# AVR64EA48 device description
Architecture: AVR8X; Family: AVR
Registers are 8-bit, read-write, reset 0x0 unless marked. A register's access mark holds for its fields unless they carry their own. Offsets are from the block's base; [hi:lo] are bit positions; {n}, {i} and the like mark numbered series; 'fields as' and 'values as' point back to an identical list.

## PORT — I/O Ports
Instances: PORTA 0x0400, PORTB 0x0420, PORTC 0x0440, PORTD 0x0460, PORTE 0x0480, PORTF 0x04A0
0x00 DIR — Data Direction
0x01 DIRSET — Data Direction Set
0x02 DIRCLR — Data Direction Clear
0x03 DIRTGL — Data Direction Toggle
0x04 OUT — Output Value
0x05 OUTSET — Output Value Set
0x06 OUTCLR — Output Value Clear
0x07 OUTTGL — Output Value Toggle
0x08 IN — Input Value
0x09 INTFLAGS — Interrupt Flags
  [7:0] INT — Pin Interrupt Flag
0x0A PORTCTRL — Port Control
  [0] SRL — Slew Rate Limit Enable
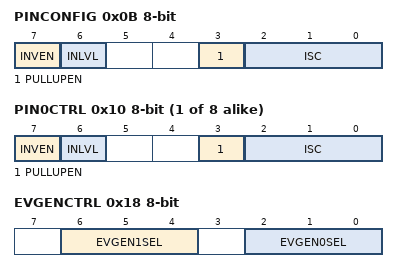
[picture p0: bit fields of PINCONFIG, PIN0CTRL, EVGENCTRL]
0x0B PINCONFIG — Pin Control Config
  [7] INVEN — Inverted I/O Enable
  [6] INLVL — Input Level Select
    0=ST (Schmitt-Trigger input level); 1=TTL (TTL Input level)
  [3] PULLUPEN — Pullup enable
  [2:0] ISC — Input/Sense Configuration
    0=INTDISABLE (Interrupt disabled but input buffer enabled); 1=BOTHEDGES (Sense Both Edges); 2=RISING (Sense Rising Edge); 3=FALLING (Sense Falling Edge); 4=INPUT_DISABLE (Digital Input Buffer disabled); 5=LEVEL (Sense low Level)
0x0C PINCTRLUPD — Pin Control Update
0x0D PINCTRLSET — Pin Control Set
0x0E PINCTRLCLR — Pin Control Clear
{0x10+i} PIN{i}CTRL (i=0..7) — Pin {i} Control
  fields as PINCONFIG
0x18 EVGENCTRL — Event Generation Control
  [6:4] EVGEN1SEL — Event Generator 1 Select
    {v}=PIN{v} (Pin {v} used as event generator) (v=0..7)
  [2:0] EVGEN0SEL — Event Generator 0 Select
    {v}=PIN{v} (Pin {v} used as event generator) (v=0..7)

## PORTMUX — Port Multiplexer
Instances: PORTMUX 0x05E0
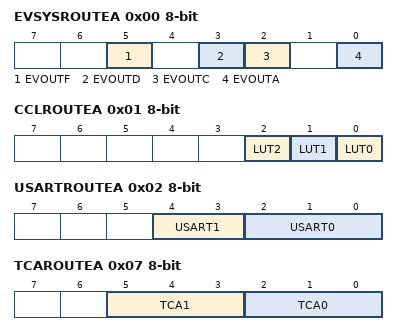
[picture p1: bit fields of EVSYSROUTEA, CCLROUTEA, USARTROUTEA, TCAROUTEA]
0x00 EVSYSROUTEA
  [5] EVOUTF — Event Output F
    0=DEFAULT (EVOUT on PF2); 1=ALT1 (EVOUT on PF7)
  [3] EVOUTD — Event Output D
    0=DEFAULT (EVOUT on PD2); 1=ALT1 (EVOUT on PD7)
  [2] EVOUTC — Event Output C
    0=DEFAULT (EVOUT on PC2); 1=ALT1 (EVOUT on PC7)
  [0] EVOUTA — Event Output A
    0=DEFAULT (EVOUT on PA2); 1=ALT1 (EVOUT on PA7)
0x01 CCLROUTEA
  [2] LUT2 — CCL Look-Up Table 2 Signals
    0=DEFAULT (Out: PD3 In: PD0, PD1, PD2); 1=ALT1 (Out: PD6 In: PD0, PD1, PD2)
  [1] LUT1 — CCL Look-Up Table 1 Signals
    0=DEFAULT (Out: PC3 In: PC0, PC1, PC2); 1=ALT1 (Out: PC6 In: PC0, PC1, PC2)
  [0] LUT0 — CCL Look-Up Table 0 Signals
    0=DEFAULT (Out: PA3 In: PA0, PA1, PA2); 1=ALT1 (Out: PA6 In: PA0, PA1, PA2)
0x02 USARTROUTEA
  [4:3] USART1 — USART1 Routing
    0=DEFAULT ({PC0, PC1, PC2, PC3}); 1=ALT1 ({PC4, PC5, PC6, PC7}); 2=ALT2 ({PD6, PD7, -, -}); 3=NONE (Not connected to any pins)
  [2:0] USART0 — USART0 Routing
    0=DEFAULT ({PA0, PA1, PA2, PA3}); 1=ALT1 ({PA4, PA5, PA6, PA7}); 2=ALT2 ({PA2,PA3, -, -}); 3=ALT3 ({PD4, PD5, PD6, PD7}); 4=ALT4 ({PC1, PC2, PC3, -}); 5=NONE (Not connected to any pins)
0x03 USARTROUTEB
  [5:4] USART2 — USART2 Routing
    0=DEFAULT ({PF0, PF1, PF2, PF3}); 1=ALT1 ({PF4, PF5,- , -}); 3=NONE (Not connected to any pins)
0x05 SPIROUTEA
  [2:0] SPI0 — SPI0 Signals
    0=DEFAULT (PA4, PA5, PA6, PA7); 1=ALT1 (PE0, PE1, PE2, PE3); 3=NONE (Not connected to any pins)
0x06 TWIROUTEA
  [1:0] TWI0 — TWI0 Signals
    0=DEFAULT ({PA2, PA3}, {PC2, PC3}); 1=ALT1 ({PA2, PA3}, {PC6, PC7}); 2=ALT2 ({PC2, PC3}, {PC6, PC7}); 3=ALT3 ({PA0, PA1}, {PC2, PC3})
0x07 TCAROUTEA
  [5:3] TCA1 — TCA1 Signals
    0=PORTB (PB0, PB1, PB2, PB3, PB4, PB5); 1=PORTC (PC4, PC5, PC6); 4=PORTA (PA4, PA5, PA6); 5=PORTD (PD4, PD5, PD6)
  [2:0] TCA0 — TCA0 Signals
    0=PORTA (PA0, PA1, PA2, PA3, PA4, PA5); 1=PORTB (PB0, PB1, PB2, PB3, PB4, PB5); 2=PORTC (PC0, PC1, PC2, PC3, PC4, PC5); 3=PORTD (PD0, PD1, PD2, PD3, PD4, PD5); 4=PORTE (PE0, PE1, PE2, PE3, PE4, PE5); 5=PORTF (PF0, PF1, PF2, PF3, PF4, PF5)
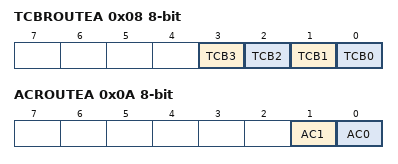
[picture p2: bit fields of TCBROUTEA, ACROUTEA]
0x08 TCBROUTEA
  [3] TCB3 — TCB3 Output
    0=DEFAULT (PB5); 1=ALT1 (PC1)
  [2] TCB2 — TCB2 Output
    0=DEFAULT (PC0); 1=ALT1 (PB4)
  [1] TCB1 — TCB1 Output
    0=DEFAULT (PA3); 1=ALT1 (PF5)
  [0] TCB0 — TCB0 Output
    0=DEFAULT (PA2); 1=ALT1 (PF4)
0x0A ACROUTEA
  [1] AC1 — Analog Comparator 1 Output
    0=DEFAULT (OUT on PA7); 1=ALT1 (OUT on PC6)
  [0] AC0 — Analog Comparator 0 Output
    0=DEFAULT (OUT on PA7); 1=ALT1 (OUT on PC6)
